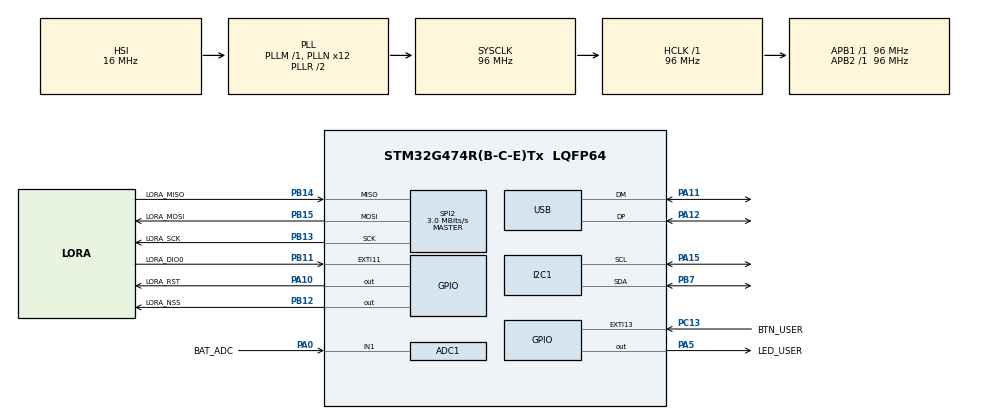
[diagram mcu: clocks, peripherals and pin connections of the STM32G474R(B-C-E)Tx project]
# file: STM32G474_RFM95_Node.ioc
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ADC1.Channel-0\#ChannelRegularConversion=ADC_CHANNEL_1
ADC1.Channel-1\#ChannelRegularConversion=ADC_CHANNEL_VREFINT
ADC1.NbrOfConversion=2
ADC1.NbrOfConversionFlag=1
ADC1.OffsetNumber-0\#ChannelRegularConversion=ADC_OFFSET_NONE
ADC1.OffsetNumber-1\#ChannelRegularConversion=ADC_OFFSET_NONE
ADC1.Rank-0\#ChannelRegularConversion=1
ADC1.Rank-1\#ChannelRegularConversion=2
ADC1.SamplingTime-0\#ChannelRegularConversion=ADC_SAMPLETIME_92CYCLES_5
ADC1.SamplingTime-1\#ChannelRegularConversion=ADC_SAMPLETIME_92CYCLES_5
ADC1.master=1
Dma.ADC1.0.Direction=DMA_PERIPH_TO_MEMORY
Dma.ADC1.0.EventEnable=DISABLE
Dma.ADC1.0.Instance=DMA1_Channel1
Dma.ADC1.0.MemDataAlignment=DMA_MDATAALIGN_HALFWORD
Dma.ADC1.0.MemInc=DMA_MINC_ENABLE
Dma.ADC1.0.Mode=DMA_NORMAL
Dma.ADC1.0.PeriphDataAlignment=DMA_PDATAALIGN_HALFWORD
Dma.ADC1.0.PeriphInc=DMA_PINC_DISABLE
Dma.ADC1.0.Polarity=HAL_DMAMUX_REQ_GEN_RISING
Dma.ADC1.0.Priority=DMA_PRIORITY_LOW
Dma.ADC1.0.RequestNumber=1
Dma.ADC1.0.SignalID=NONE
Dma.ADC1.0.SyncEnable=DISABLE
Dma.ADC1.0.SyncPolarity=HAL_DMAMUX_SYNC_NO_EVENT
Dma.ADC1.0.SyncRequestNumber=1
Dma.ADC1.0.SyncSignalID=NONE
Dma.Request0=ADC1
FREERTOS.Tasks01=radio_task,40,256,StartRadioTask,Default,NULL,Static,radio_taskBuffer,radio_taskControlBlock;sensor_task,25,256,StartSensorTask,Default,NULL,Static,sensor_taskBuffer,sensor_taskControlBlock;telemetry_task,24,256,StartTelemetryTask,Default,NULL,Static,telemetry_taskBuffer,telemetry_taskControlBlock;ui_task,8,256,StartUiTask,Default,NULL,Static,ui_taskBuffer,ui_taskControlBlock;cli_task,8,256,StartCliTask,Default,NULL,Static,cli_taskBuffer,cli_taskControlBlock
FREERTOS.configUSE_NEWLIB_REENTRANT=1
I2C1.Timing=0x20B17DB6
Mcu.Family=STM32G4
Mcu.Name=STM32G474R(B-C-E)Tx
Mcu.Package=LQFP64
NUCLEO-G474RE.LD2=true
NUCLEO-G474RE.VCP=true
NVIC.DMA1_Channel1_IRQn=true\:5\:0\:false\:false\:true\:true\:false\:true\:true
NVIC.EXTI15_10_IRQn=true\:5\:0\:false\:false\:true\:true\:true\:true\:true
NVIC.PriorityGroup=NVIC_PRIORITYGROUP_4
NVIC.RCC_IRQn=true\:5\:0\:false\:false\:true\:true\:true\:false\:true
NVIC.TIM1_UP_TIM16_IRQn=true\:15\:0\:false\:false\:true\:false\:false\:true\:true
NVIC.TimeBase=TIM1_UP_TIM16_IRQn
NVIC.TimeBaseIP=TIM1
NVIC.USB_LP_IRQn=true\:5\:0\:false\:false\:true\:true\:false\:true\:true
PA0.GPIO_Label=BAT_ADC
PA0.Mode=IN1-Single-Ended
PA0.Signal=ADC1_IN1
PA10.GPIO_Label=LORA_RST
PA10.PinState=GPIO_PIN_SET
PA10.Signal=GPIO_Output
PA11.Mode=Device
PA11.Signal=USB_DM
PA12.Mode=Device
PA12.Signal=USB_DP
PA13.GPIO_Label=T_SWDIO
PA13.Signal=SYS_JTMS-SWDIO
PA14.GPIO_Label=T_SWCLK
PA14.Signal=SYS_JTCK-SWCLK
PA15.Mode=I2C
PA15.Signal=I2C1_SCL
PA2.Signal=LPUART1_TX
PA3.Signal=LPUART1_RX
PA5.GPIO_Label=LED_USER
PA5.Signal=GPIO_Output
PB11.GPIO_Label=LORA_DIO0
PB11.Signal=GPXTI11
PB12.GPIO_Label=LORA_NSS
PB12.Signal=GPIO_Output
PB13.GPIO_Label=LORA_SCK
PB13.Mode=Full_Duplex_Master
PB13.Signal=SPI2_SCK
PB14.GPIO_Label=LORA_MISO
PB14.Mode=Full_Duplex_Master
PB14.Signal=SPI2_MISO
PB15.GPIO_Label=LORA_MOSI
PB15.Mode=Full_Duplex_Master
PB15.Signal=SPI2_MOSI
PB3.GPIO_Label=T_SWO
PB3.Signal=SYS_JTDO-SWO
PB7.Mode=I2C
PB7.Signal=I2C1_SDA
PC13.GPIO_Label=BTN_USER
PC13.Signal=GPXTI13
PC14-OSC32_IN.GPIO_Label=RCC_OSC32_IN
PC14-OSC32_IN.Mode=LSE-External-Oscillator
PC14-OSC32_IN.Signal=RCC_OSC32_IN
PC15-OSC32_OUT.GPIO_Label=RCC_OSC32_OUT
PC15-OSC32_OUT.Mode=LSE-External-Oscillator
PC15-OSC32_OUT.Signal=RCC_OSC32_OUT
PF0-OSC_IN.GPIO_Label=RCC_OSC_IN
PF0-OSC_IN.Mode=HSE-External-Oscillator
PF0-OSC_IN.Signal=RCC_OSC_IN
PF1-OSC_OUT.GPIO_Label=RCC_OSC_OUT
PF1-OSC_OUT.Mode=HSE-External-Oscillator
PF1-OSC_OUT.Signal=RCC_OSC_OUT
ProjectManager.HeapSize=0x200
ProjectManager.StackSize=0x400
ProjectManager.TargetToolchain=STM32CubeIDE
RCC.ADC12Freq_Value=96000000
RCC.ADC345Freq_Value=96000000
RCC.AHBFreq_Value=96000000
RCC.APB1Freq_Value=96000000
RCC.APB1TimFreq_Value=96000000
RCC.APB2Freq_Value=96000000
RCC.APB2TimFreq_Value=96000000
RCC.CortexFreq_Value=96000000
RCC.EXTERNAL_CLOCK_VALUE=12288000
RCC.HCLKFreq_Value=96000000
RCC.HSE_VALUE=24000000
RCC.HSI48_VALUE=48000000
RCC.HSI_VALUE=16000000
RCC.PLLN=12
RCC.PLLQ=RCC_PLLQ_DIV4
RCC.RTCClockSelection=RCC_RTCCLKSOURCE_LSE
RCC.SYSCLKFreq_VALUE=96000000
RCC.SYSCLKSource=RCC_SYSCLKSOURCE_PLLCLK
RCC.USBFreq_Value=48000000
RCC.VCOOutputFreq_Value=192000000
SPI2.BaudRatePrescaler=SPI_BAUDRATEPRESCALER_32
SPI2.CalculateBaudRate=3.0 MBits/s
SPI2.DataSize=SPI_DATASIZE_8BIT
SPI2.Direction=SPI_DIRECTION_2LINES
SPI2.Mode=SPI_MODE_MASTER
SPI2.VirtualType=VM_MASTER
USB_DEVICE.CLASS_NAME_FS=CDC
USB_DEVICE.VirtualMode=Cdc
USB_DEVICE.VirtualModeFS=Cdc_FS
VP_ADC1_Vref_Input.Mode=IN-Vrefint
VP_FREERTOS_VS_CMSIS_V2.Mode=CMSIS_V2
VP_NUCLEO-G474RE_VS_BSP_COMMON.Mode=COMMON
VP_SYS_VS_DBSignals.Mode=DisableDeadBatterySignals
VP_SYS_VS_tim1.Mode=TIM1
VP_USB_DEVICE_VS_USB_DEVICE_CDC_FS.Mode=CDC_FS
board=NUCLEO-G474RE

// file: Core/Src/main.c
/* USER CODE BEGIN Header */
/**
  ******************************************************************************
  * @file           : main.c
  * @brief          : Main program body
  ******************************************************************************
  * @attention
  *
  * Copyright (c) 2026 STMicroelectronics.
  * All rights reserved.
  *
  * This software is licensed under terms that can be found in the LICENSE file
  * in the root directory of this software component.
  * If no LICENSE file comes with this software, it is provided AS-IS.
  *
  ******************************************************************************
  */
/* USER CODE END Header */
#include "main.h"
#include "cmsis_os.h"
#include "usb_device.h"

typedef StaticTask_t osStaticThreadDef_t;

COM_InitTypeDef BspCOMInit;
ADC_HandleTypeDef hadc1;
DMA_HandleTypeDef hdma_adc1;

I2C_HandleTypeDef hi2c1;

SPI_HandleTypeDef hspi2;

/* Definitions for radio_task */
osThreadId_t radio_taskHandle;
uint32_t radio_taskBuffer[ 256 ];
osStaticThreadDef_t radio_taskControlBlock;
const osThreadAttr_t radio_task_attributes = {
  .name = "radio_task",
  .stack_mem = &radio_taskBuffer[0],
  .stack_size = sizeof(radio_taskBuffer),
  .cb_mem = &radio_taskControlBlock,
  .cb_size = sizeof(radio_taskControlBlock),
  .priority = (osPriority_t) osPriorityHigh,
};
/* Definitions for sensor_task */
osThreadId_t sensor_taskHandle;
uint32_t sensor_taskBuffer[ 256 ];
osStaticThreadDef_t sensor_taskControlBlock;
const osThreadAttr_t sensor_task_attributes = {
  .name = "sensor_task",
  .stack_mem = &sensor_taskBuffer[0],
  .stack_size = sizeof(sensor_taskBuffer),
  .cb_mem = &sensor_taskControlBlock,
  .cb_size = sizeof(sensor_taskControlBlock),
  .priority = (osPriority_t) osPriorityNormal1,
};
/* Definitions for telemetry_task */
osThreadId_t telemetry_taskHandle;
uint32_t telemetry_taskBuffer[ 256 ];
osStaticThreadDef_t telemetry_taskControlBlock;
const osThreadAttr_t telemetry_task_attributes = {
  .name = "telemetry_task",
  .stack_mem = &telemetry_taskBuffer[0],
  .stack_size = sizeof(telemetry_taskBuffer),
  .cb_mem = &telemetry_taskControlBlock,
  .cb_size = sizeof(telemetry_taskControlBlock),
  .priority = (osPriority_t) osPriorityNormal,
};
/* Definitions for ui_task */
osThreadId_t ui_taskHandle;
uint32_t ui_taskBuffer[ 256 ];
osStaticThreadDef_t ui_taskControlBlock;
const osThreadAttr_t ui_task_attributes = {
  .name = "ui_task",
  .stack_mem = &ui_taskBuffer[0],
  .stack_size = sizeof(ui_taskBuffer),
  .cb_mem = &ui_taskControlBlock,
  .cb_size = sizeof(ui_taskControlBlock),
  .priority = (osPriority_t) osPriorityLow,
};
/* Definitions for cli_task */
osThreadId_t cli_taskHandle;
uint32_t cli_taskBuffer[ 256 ];
osStaticThreadDef_t cli_taskControlBlock;
const osThreadAttr_t cli_task_attributes = {
  .name = "cli_task",
  .stack_mem = &cli_taskBuffer[0],
  .stack_size = sizeof(cli_taskBuffer),
  .cb_mem = &cli_taskControlBlock,
  .cb_size = sizeof(cli_taskControlBlock),
  .priority = (osPriority_t) osPriorityLow,
};
/* USER CODE BEGIN PV */
#define DEVICE_MODE_TX 1
#define DEVICE_MODE_RX 0

#define DEVICE_MODE DEVICE_MODE_RX
/* USER CODE END PV */

void SystemClock_Config(void);
static void MX_GPIO_Init(void);
static void MX_DMA_Init(void);
static void MX_SPI2_Init(void);
static void MX_I2C1_Init(void);
static void MX_ADC1_Init(void);
void StartRadioTask(void *argument);
void StartSensorTask(void *argument);
void StartTelemetryTask(void *argument);
void StartUiTask(void *argument);
void StartCliTask(void *argument);

int main(void)
{

  /* MCU Configuration--------------------------------------------------------*/

  /* Reset of all peripherals, Initializes the Flash interface and the Systick. */
  HAL_Init();

  /* Configure the system clock */
  SystemClock_Config();

  /* Initialize all configured peripherals */
  MX_GPIO_Init();
  MX_DMA_Init();
  MX_SPI2_Init();
  MX_I2C1_Init();
  MX_ADC1_Init();

  /* Init scheduler */
  osKernelInitialize();

  /* Create the thread(s) */
  /* creation of radio_task */
  radio_taskHandle = osThreadNew(StartRadioTask, NULL, &radio_task_attributes);

  /* creation of sensor_task */
  sensor_taskHandle = osThreadNew(StartSensorTask, NULL, &sensor_task_attributes);

  /* creation of telemetry_task */
  telemetry_taskHandle = osThreadNew(StartTelemetryTask, NULL, &telemetry_task_attributes);

  /* creation of ui_task */
  ui_taskHandle = osThreadNew(StartUiTask, NULL, &ui_task_attributes);

  /* creation of cli_task */
  cli_taskHandle = osThreadNew(StartCliTask, NULL, &cli_task_attributes);

  /* Initialize led */
  BSP_LED_Init(LED_GREEN);

  /* Initialize COM1 port (115200, 8 bits (7-bit data + 1 stop bit), no parity */
  BspCOMInit.BaudRate   = 115200;
  BspCOMInit.WordLength = COM_WORDLENGTH_8B;
  BspCOMInit.StopBits   = COM_STOPBITS_1;
  BspCOMInit.Parity     = COM_PARITY_NONE;
  BspCOMInit.HwFlowCtl  = COM_HWCONTROL_NONE;
  if (BSP_COM_Init(COM1, &BspCOMInit) != BSP_ERROR_NONE)
  {
    Error_Handler();
  }

  /* Start scheduler */
  osKernelStart();

  /* We should never get here as control is now taken by the scheduler */

  /* Infinite loop */
  while (1)
  {

  }
}

void SystemClock_Config(void)
{
  RCC_OscInitTypeDef RCC_OscInitStruct = {0};
  RCC_ClkInitTypeDef RCC_ClkInitStruct = {0};

  /** Configure the main internal regulator output voltage
  */
  HAL_PWREx_ControlVoltageScaling(PWR_REGULATOR_VOLTAGE_SCALE1);

  /** Initializes the RCC Oscillators according to the specified parameters
  * in the RCC_OscInitTypeDef structure.
  */
  RCC_OscInitStruct.OscillatorType = RCC_OSCILLATORTYPE_HSI;
  RCC_OscInitStruct.HSIState = RCC_HSI_ON;
  RCC_OscInitStruct.HSICalibrationValue = RCC_HSICALIBRATION_DEFAULT;
  RCC_OscInitStruct.PLL.PLLState = RCC_PLL_ON;
  RCC_OscInitStruct.PLL.PLLSource = RCC_PLLSOURCE_HSI;
  RCC_OscInitStruct.PLL.PLLM = RCC_PLLM_DIV1;
  RCC_OscInitStruct.PLL.PLLN = 12;
  RCC_OscInitStruct.PLL.PLLP = RCC_PLLP_DIV2;
  RCC_OscInitStruct.PLL.PLLQ = RCC_PLLQ_DIV4;
  RCC_OscInitStruct.PLL.PLLR = RCC_PLLR_DIV2;
  if (HAL_RCC_OscConfig(&RCC_OscInitStruct) != HAL_OK)
  {
    Error_Handler();
  }

  /** Initializes the CPU, AHB and APB buses clocks
  */
  RCC_ClkInitStruct.ClockType = RCC_CLOCKTYPE_HCLK|RCC_CLOCKTYPE_SYSCLK
                              |RCC_CLOCKTYPE_PCLK1|RCC_CLOCKTYPE_PCLK2;
  RCC_ClkInitStruct.SYSCLKSource = RCC_SYSCLKSOURCE_PLLCLK;
  RCC_ClkInitStruct.AHBCLKDivider = RCC_SYSCLK_DIV1;
  RCC_ClkInitStruct.APB1CLKDivider = RCC_HCLK_DIV1;
  RCC_ClkInitStruct.APB2CLKDivider = RCC_HCLK_DIV1;

  if (HAL_RCC_ClockConfig(&RCC_ClkInitStruct, FLASH_LATENCY_3) != HAL_OK)
  {
    Error_Handler();
  }
}

static void MX_ADC1_Init(void)
{

  ADC_MultiModeTypeDef multimode = {0};
  ADC_ChannelConfTypeDef sConfig = {0};

  /** Common config
  */
  hadc1.Instance = ADC1;
  hadc1.Init.ClockPrescaler = ADC_CLOCK_SYNC_PCLK_DIV2;
  hadc1.Init.Resolution = ADC_RESOLUTION_12B;
  hadc1.Init.DataAlign = ADC_DATAALIGN_RIGHT;
  hadc1.Init.GainCompensation = 0;
  hadc1.Init.ScanConvMode = ADC_SCAN_ENABLE;
  hadc1.Init.EOCSelection = ADC_EOC_SINGLE_CONV;
  hadc1.Init.LowPowerAutoWait = DISABLE;
  hadc1.Init.ContinuousConvMode = DISABLE;
  hadc1.Init.NbrOfConversion = 2;
  hadc1.Init.DiscontinuousConvMode = DISABLE;
  hadc1.Init.ExternalTrigConv = ADC_SOFTWARE_START;
  hadc1.Init.ExternalTrigConvEdge = ADC_EXTERNALTRIGCONVEDGE_NONE;
  hadc1.Init.DMAContinuousRequests = DISABLE;
  hadc1.Init.Overrun = ADC_OVR_DATA_PRESERVED;
  hadc1.Init.OversamplingMode = DISABLE;
  if (HAL_ADC_Init(&hadc1) != HAL_OK)
  {
    Error_Handler();
  }

  /** Configure the ADC multi-mode
  */
  multimode.Mode = ADC_MODE_INDEPENDENT;
  if (HAL_ADCEx_MultiModeConfigChannel(&hadc1, &multimode) != HAL_OK)
  {
    Error_Handler();
  }

  /** Configure Regular Channel
  */
  sConfig.Channel = ADC_CHANNEL_1;
  sConfig.Rank = ADC_REGULAR_RANK_1;
  sConfig.SamplingTime = ADC_SAMPLETIME_92CYCLES_5;
  sConfig.SingleDiff = ADC_SINGLE_ENDED;
  sConfig.OffsetNumber = ADC_OFFSET_NONE;
  sConfig.Offset = 0;
  if (HAL_ADC_ConfigChannel(&hadc1, &sConfig) != HAL_OK)
  {
    Error_Handler();
  }

  /** Configure Regular Channel
  */
  sConfig.Channel = ADC_CHANNEL_VREFINT;
  sConfig.Rank = ADC_REGULAR_RANK_2;
  if (HAL_ADC_ConfigChannel(&hadc1, &sConfig) != HAL_OK)
  {
    Error_Handler();
  }

}

static void MX_I2C1_Init(void)
{

  hi2c1.Instance = I2C1;
  hi2c1.Init.Timing = 0x20B17DB6;
  hi2c1.Init.OwnAddress1 = 0;
  hi2c1.Init.AddressingMode = I2C_ADDRESSINGMODE_7BIT;
  hi2c1.Init.DualAddressMode = I2C_DUALADDRESS_DISABLE;
  hi2c1.Init.OwnAddress2 = 0;
  hi2c1.Init.OwnAddress2Masks = I2C_OA2_NOMASK;
  hi2c1.Init.GeneralCallMode = I2C_GENERALCALL_DISABLE;
  hi2c1.Init.NoStretchMode = I2C_NOSTRETCH_DISABLE;
  if (HAL_I2C_Init(&hi2c1) != HAL_OK)
  {
    Error_Handler();
  }

  /** Configure Analogue filter
  */
  if (HAL_I2CEx_ConfigAnalogFilter(&hi2c1, I2C_ANALOGFILTER_ENABLE) != HAL_OK)
  {
    Error_Handler();
  }

  /** Configure Digital filter
  */
  if (HAL_I2CEx_ConfigDigitalFilter(&hi2c1, 0) != HAL_OK)
  {
    Error_Handler();
  }

}

static void MX_SPI2_Init(void)
{

  /* SPI2 parameter configuration*/
  hspi2.Instance = SPI2;
  hspi2.Init.Mode = SPI_MODE_MASTER;
  hspi2.Init.Direction = SPI_DIRECTION_2LINES;
  hspi2.Init.DataSize = SPI_DATASIZE_8BIT;
  hspi2.Init.CLKPolarity = SPI_POLARITY_LOW;
  hspi2.Init.CLKPhase = SPI_PHASE_1EDGE;
  hspi2.Init.NSS = SPI_NSS_SOFT;
  hspi2.Init.BaudRatePrescaler = SPI_BAUDRATEPRESCALER_32;
  hspi2.Init.FirstBit = SPI_FIRSTBIT_MSB;
  hspi2.Init.TIMode = SPI_TIMODE_DISABLE;
  hspi2.Init.CRCCalculation = SPI_CRCCALCULATION_DISABLE;
  hspi2.Init.CRCPolynomial = 7;
  hspi2.Init.CRCLength = SPI_CRC_LENGTH_DATASIZE;
  hspi2.Init.NSSPMode = SPI_NSS_PULSE_ENABLE;
  if (HAL_SPI_Init(&hspi2) != HAL_OK)
  {
    Error_Handler();
  }

}

static void MX_DMA_Init(void)
{

  /* DMA controller clock enable */
  __HAL_RCC_DMAMUX1_CLK_ENABLE();
  __HAL_RCC_DMA1_CLK_ENABLE();

  /* DMA interrupt init */
  /* DMA1_Channel1_IRQn interrupt configuration */
  HAL_NVIC_SetPriority(DMA1_Channel1_IRQn, 5, 0);
  HAL_NVIC_EnableIRQ(DMA1_Channel1_IRQn);

}

static void MX_GPIO_Init(void)
{
  GPIO_InitTypeDef GPIO_InitStruct = {0};

  /* GPIO Ports Clock Enable */
  __HAL_RCC_GPIOC_CLK_ENABLE();
  __HAL_RCC_GPIOF_CLK_ENABLE();
  __HAL_RCC_GPIOA_CLK_ENABLE();
  __HAL_RCC_GPIOB_CLK_ENABLE();

  /*Configure GPIO pin Output Level */
  HAL_GPIO_WritePin(LED_USER_GPIO_Port, LED_USER_Pin, GPIO_PIN_RESET);

  /*Configure GPIO pin Output Level */
  HAL_GPIO_WritePin(LORA_NSS_GPIO_Port, LORA_NSS_Pin, GPIO_PIN_RESET);

  /*Configure GPIO pin Output Level */
  HAL_GPIO_WritePin(LORA_RST_GPIO_Port, LORA_RST_Pin, GPIO_PIN_SET);

  /*Configure GPIO pin : BTN_USER_Pin */
  GPIO_InitStruct.Pin = BTN_USER_Pin;
  GPIO_InitStruct.Mode = GPIO_MODE_IT_RISING;
  GPIO_InitStruct.Pull = GPIO_NOPULL;
  HAL_GPIO_Init(BTN_USER_GPIO_Port, &GPIO_InitStruct);

  /*Configure GPIO pins : LED_USER_Pin LORA_RST_Pin */
  GPIO_InitStruct.Pin = LED_USER_Pin|LORA_RST_Pin;
  GPIO_InitStruct.Mode = GPIO_MODE_OUTPUT_PP;
  GPIO_InitStruct.Pull = GPIO_NOPULL;
  GPIO_InitStruct.Speed = GPIO_SPEED_FREQ_LOW;
  HAL_GPIO_Init(GPIOA, &GPIO_InitStruct);

  /*Configure GPIO pin : LORA_DIO0_Pin */
  GPIO_InitStruct.Pin = LORA_DIO0_Pin;
  GPIO_InitStruct.Mode = GPIO_MODE_IT_RISING;
  GPIO_InitStruct.Pull = GPIO_NOPULL;
  HAL_GPIO_Init(LORA_DIO0_GPIO_Port, &GPIO_InitStruct);

  /*Configure GPIO pin : LORA_NSS_Pin */
  GPIO_InitStruct.Pin = LORA_NSS_Pin;
  GPIO_InitStruct.Mode = GPIO_MODE_OUTPUT_PP;
  GPIO_InitStruct.Pull = GPIO_NOPULL;
  GPIO_InitStruct.Speed = GPIO_SPEED_FREQ_LOW;
  HAL_GPIO_Init(LORA_NSS_GPIO_Port, &GPIO_InitStruct);

  /* EXTI interrupt init*/
  HAL_NVIC_SetPriority(EXTI15_10_IRQn, 5, 0);
  HAL_NVIC_EnableIRQ(EXTI15_10_IRQn);

}

void StartRadioTask(void *argument)
{
  /* init code for USB_Device */
  MX_USB_Device_Init();
  for(;;)
  {
    osDelay(1);
  }
}

void StartSensorTask(void *argument)
{
  for(;;)
  {
    osDelay(1);
  }
}

void StartTelemetryTask(void *argument)
{
  for(;;)
  {
    osDelay(1);
  }
}

void StartUiTask(void *argument)
{
  for(;;)
  {
    osDelay(1);
  }
}

void StartCliTask(void *argument)
{
  for(;;)
  {
    osDelay(1);
  }
}

void HAL_TIM_PeriodElapsedCallback(TIM_HandleTypeDef *htim)
{
  if (htim->Instance == TIM1)
  {
    HAL_IncTick();
  }
}

void Error_Handler(void)
{
  __disable_irq();
  while (1)
  {
  }
}
